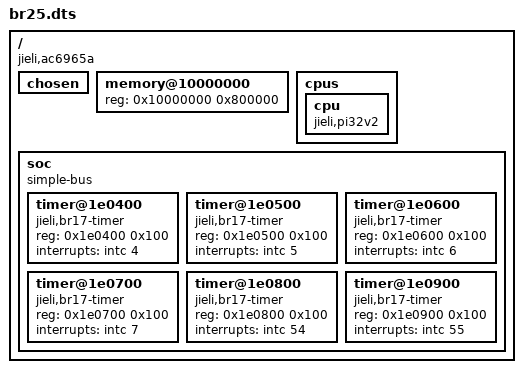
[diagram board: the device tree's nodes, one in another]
/dts-v1/;

/ {
	#address-cells = <1>;
	#size-cells = <1>;
	compatible = "jieli,ac6965a", "jieli,ac696n", "jieli,br25";

	chosen {
		
	};

	/* kkm fake memory! */
	memory@10000000 {
		reg = <0x10000000 0x800000>;
	};

	cpus {
		cpu {
			compatible = "jieli,pi32v2";
		};
	};

	soc {
		#address-cells = <1>;
		#size-cells = <1>;
		compatible = "simple-bus";
		ranges;

		timer@1e0400 {
			compatible = "jieli,br17-timer";
			reg = <0x1e0400 0x100>;
			interrupts = <&intc 4>;
		};

		timer@1e0500 {
			compatible = "jieli,br17-timer";
			reg = <0x1e0500 0x100>;
			interrupts = <&intc 5>;
		};

		timer@1e0600 {
			compatible = "jieli,br17-timer";
			reg = <0x1e0600 0x100>;
			interrupts = <&intc 6>;
		};

		timer@1e0700 {
			compatible = "jieli,br17-timer";
			reg = <0x1e0700 0x100>;
			interrupts = <&intc 7>;
		};

		timer@1e0800 {
			compatible = "jieli,br17-timer";
			reg = <0x1e0800 0x100>;
			interrupts = <&intc 54>;
		};

		timer@1e0900 {
			compatible = "jieli,br17-timer";
			reg = <0x1e0900 0x100>;
			interrupts = <&intc 55>;
		};
	};
};
